# L3INIT_CM_CORE register map
Vendor: Texas Instruments
Peripheral module from a debugger description file (folder omap5430_ES2_PUBLIC).
Registers are 32-bit, access per field, reset 0x70000 unless marked. A register's access mark holds for its fields unless they carry their own. Offsets are as the file gives them; lines under a group give offsets from that group; [hi:lo] are bit positions; {n}, {i} and the like mark numbered series; 'fields as' and 'values as' point back to an identical list; <NAME> marks a mode.

## L3INIT_CM_CORE
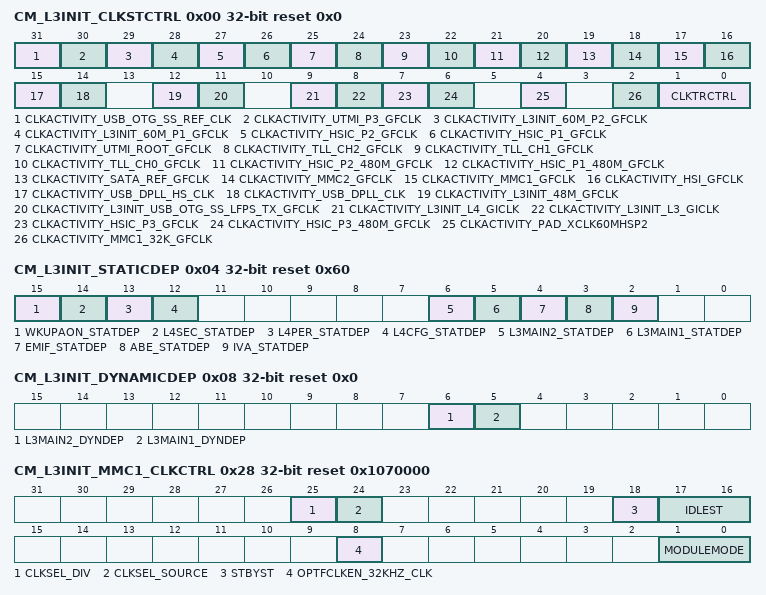
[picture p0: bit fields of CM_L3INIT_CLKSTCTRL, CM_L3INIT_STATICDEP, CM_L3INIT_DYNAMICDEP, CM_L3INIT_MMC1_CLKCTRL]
0x00 CM_L3INIT_CLKSTCTRL reset 0x0 — This register enables the domain power state transition. It controls the HW supervised domain power state transition between ON-ACTIVE and ON-INACTIVE states. It also holds one status bit per clock input of the domain.
  [31] CLKACTIVITY_USB_OTG_SS_REF_CLK ro — This field indicates the state of the USB_OTG_SS_REF_CLK clock in the domain. [warm reset insensitive]
    1=Act (Corresponding clock is running or gating/ungating transition is on-going); 0=Inact (Corresponding clock is definitely gated)
  [30] CLKACTIVITY_UTMI_P3_GFCLK ro — This field indicates the state of the UTMI_P3_GFCLK clock in the domain. [warm reset insensitive]
    values as CLKACTIVITY_USB_OTG_SS_REF_CLK
  [29] CLKACTIVITY_L3INIT_60M_P2_GFCLK ro — This field indicates the state of the INIT_60M_P2_GFCLK clock in the domain. [warm reset insensitive]
    0=Inact (Corresponding clock is definitely gated); 1=Act (Corresponding clock is running or gating/ungating transition is on-going)
  [28] CLKACTIVITY_L3INIT_60M_P1_GFCLK ro — This field indicates the state of the INIT_60M_P1_GFCLK clock in the domain. [warm reset insensitive]
    values as CLKACTIVITY_L3INIT_60M_P2_GFCLK
  [27] CLKACTIVITY_HSIC_P2_GFCLK ro — This field indicates the state of the HSIC_P2_GFCLK clock in the domain. [warm reset insensitive]
    values as CLKACTIVITY_L3INIT_60M_P2_GFCLK
  [26] CLKACTIVITY_HSIC_P1_GFCLK ro — This field indicates the state of the HSIC_P1_GFCLK clock in the domain. [warm reset insensitive]
    values as CLKACTIVITY_L3INIT_60M_P2_GFCLK
  [25] CLKACTIVITY_UTMI_ROOT_GFCLK ro — This field indicates the state of the UTMI_ROOT_GFCLK clock in the domain. [warm reset insensitive]
    values as CLKACTIVITY_L3INIT_60M_P2_GFCLK
  [24] CLKACTIVITY_TLL_CH2_GFCLK ro — This field indicates the state of the TLL_CH2_GFCLK clock in the domain. [warm reset insensitive]
    values as CLKACTIVITY_L3INIT_60M_P2_GFCLK
  [23] CLKACTIVITY_TLL_CH1_GFCLK ro — This field indicates the state of the TLL_CH1_GFCLK clock in the domain. [warm reset insensitive]
    values as CLKACTIVITY_L3INIT_60M_P2_GFCLK
  [22] CLKACTIVITY_TLL_CH0_GFCLK ro — This field indicates the state of the TLL_CH0_GFCLK clock in the domain. [warm reset insensitive]
    values as CLKACTIVITY_L3INIT_60M_P2_GFCLK
  [21] CLKACTIVITY_HSIC_P2_480M_GFCLK ro — This field indicates the state of the HSIC_P2_480M_GFCLK clock in the domain. [warm reset insensitive]
    values as CLKACTIVITY_L3INIT_60M_P2_GFCLK
  [20] CLKACTIVITY_HSIC_P1_480M_GFCLK ro — This field indicates the state of the HSIC_P1_480M_GFCLK clock in the domain. [warm reset insensitive]
    values as CLKACTIVITY_L3INIT_60M_P2_GFCLK
  [19] CLKACTIVITY_SATA_REF_GFCLK ro — This field indicates the state of the SATA_REF_GFCLK clock in the domain. [warm reset insensitive] read 0x0: Corresponding clock is definitely gated read 0x1: Corresponding clock is running or gating/ungating transition is on-going
  [18] CLKACTIVITY_MMC2_GFCLK ro — This field indicates the state of the MMC2_GFCLK clock in the domain. [warm reset insensitive]
    values as CLKACTIVITY_L3INIT_60M_P2_GFCLK
  [17] CLKACTIVITY_MMC1_GFCLK ro — This field indicates the state of the MMC1_GFCLK clock in the domain. [warm reset insensitive]
    values as CLKACTIVITY_L3INIT_60M_P2_GFCLK
  [16] CLKACTIVITY_HSI_GFCLK ro — This field indicates the state of the HSI_GFCLK clock in the domain. [warm reset insensitive]
    values as CLKACTIVITY_L3INIT_60M_P2_GFCLK
  [15] CLKACTIVITY_USB_DPLL_HS_CLK ro — This field indicates the state of the USB_DPLL_HS_CLK clock in the domain. [warm reset insensitive]
    values as CLKACTIVITY_L3INIT_60M_P2_GFCLK
  [14] CLKACTIVITY_USB_DPLL_CLK ro — This field indicates the state of the USB_DPLL_CLK clock in the domain. [warm reset insensitive]
    values as CLKACTIVITY_L3INIT_60M_P2_GFCLK
  [12] CLKACTIVITY_L3INIT_48M_GFCLK ro — This field indicates the state of the L3INIT_48M_GFCLK clock in the domain. [warm reset insensitive]
    values as CLKACTIVITY_L3INIT_60M_P2_GFCLK
  [11] CLKACTIVITY_L3INIT_USB_OTG_SS_LFPS_TX_GFCLK ro — This field indicates the state of the L3INIT_USB_OTG_SS_LFPS_TX_GFCLK clock in the domain.[warm reset insensitive]
    values as CLKACTIVITY_L3INIT_60M_P2_GFCLK
  [9] CLKACTIVITY_L3INIT_L4_GICLK ro — This field indicates the state of the L3INIT_L4_GICLK clock in the domain. [warm reset insensitive]
    values as CLKACTIVITY_L3INIT_60M_P2_GFCLK
  [8] CLKACTIVITY_L3INIT_L3_GICLK ro — This field indicates the state of the L3INIT_L3_GICLK clock in the domain. [warm reset insensitive]
    values as CLKACTIVITY_L3INIT_60M_P2_GFCLK
  [7] CLKACTIVITY_HSIC_P3_GFCLK ro — This field indicates the state of the HSIC_P3_GFCLK clock in the domain. [warm reset insensitive]
    values as CLKACTIVITY_L3INIT_60M_P2_GFCLK
  [6] CLKACTIVITY_HSIC_P3_480M_GFCLK ro — This field indicates the state of the HSIC_P3_480M_GFCLK clock in the domain. [warm reset insensitive]
    values as CLKACTIVITY_L3INIT_60M_P2_GFCLK
  [4] CLKACTIVITY_PAD_XCLK60MHSP2 ro — This field indicates the state of the XCLK60MHSP2 clock in the domain. [warm reset insensitive]
    values as CLKACTIVITY_L3INIT_60M_P2_GFCLK
  [2] CLKACTIVITY_MMC1_32K_GFCLK ro — This field indicates the state of the MMC1_32K_GFCLK clock in the domain. [warm reset insensitive]
    0=Corresponding_clock_is_definitely_gated; 1=CLKACTIVITY_MMC1_32K_GFCLK_1_r (Corresponding clock is running or gating/ungating transition is on-going)
  [1:0] CLKTRCTRL rw — Controls the clock state transition of the L3INIT clock domain.
    0=NO_SLEEP (NO_SLEEP: Sleep transition cannot be initiated. Wakeup transition may however occur.); 1=SW_SLEEP (SW_SLEEP: Start a software forced sleep transition on the domain.); 2=SW_WKUP (SW_WKUP: Start a software forced wake-up transition on the domain.); 3=HW_AUTO (HW_AUTO: Automatic transition is enabled. Sleep and wakeup transition are based upon hardware conditions.)
0x04 CM_L3INIT_STATICDEP reset 0x60 — This register controls the static domain dependencies from L3INIT domain towards 'target' domains. It is relevant only for domain having system initiator(s).
  [15] WKUPAON_STATDEP rw — Static dependency towards WKUPAON clock domain
    0=Disabled (Dependency is disabled); 1=Enabled (Dependency is enabled)
  [14] L4SEC_STATDEP rw — Static dependency towards L4SEC clock domain
    0=Dependency_is_disabled; 1=Dependency_is_enabled
  [13] L4PER_STATDEP rw — Static dependency towards L4_PER clock domain
    values as WKUPAON_STATDEP
  [12] L4CFG_STATDEP rw — Static dependency towards L4_CFG clock domain
    values as WKUPAON_STATDEP
  [6] L3MAIN2_STATDEP ro — Static dependency towards L3_MAIN2 clock domain
    1=Enabled (Dependency is enabled)
  [5] L3MAIN1_STATDEP ro — Static dependency towards L3_MAIN1 clock domain
    1=Enabled (Dependency is enabled)
  [4] EMIF_STATDEP rw — Static dependency towards EMIF clock domain
    values as WKUPAON_STATDEP
  [3] ABE_STATDEP rw — Static dependency towards ABE clock domain
    values as WKUPAON_STATDEP
  [2] IVA_STATDEP rw — Static dependency towards IVA clock domain
    values as WKUPAON_STATDEP
0x08 CM_L3INIT_DYNAMICDEP ro reset 0x0 — This register controls the dynamic domain depedencies from L3INIT domain towards 'target' domains. It is relevant only for domain having INTRCONN master port(s).
  [6] L3MAIN2_DYNDEP — Dynamic dependency towards L3_MAIN2 clock domain
    0=Disabled (Dependency is disabled)
  [5] L3MAIN1_DYNDEP — Dynamic dependency towards L3_MAIN1 clock domain
    0=Disabled (Dependency is disabled)
0x28 CM_L3INIT_MMC1_CLKCTRL reset 0x1070000 — This register manages the MMC1 clocks.
  [25] CLKSEL_DIV rw — MMC1 clock divide ratio
    0=MMC1_OPP_NOM._0 (MMC1 clock is divided by 1, to be used for OPP_NOM.); 1=MMC1_clock_is_divided_by_2
  [24] CLKSEL_SOURCE rw — Selects the source of the functional clock.
    0=SEL_128M (128MHz clock derived from DPLL_PER is selected); 1=SEL_192M (192MHz clock derived from DPLL_PER is selected)
  [18] STBYST ro — Module standby status. [warm reset insensitive]
    0=Func (Module is functional (not in standby)); 1=Standby (Module is in standby)
  [17:16] IDLEST ro — Module idle status. [warm reset insensitive]
    0=Func (Module is fully functional, including INTRCONN); 1=Trans (Module is performing transition: wakeup, or sleep, or sleep abortion); 2=Idle (Module is in Idle mode (only INTRCONN part). It is functional if using separate functional clock); 3=Disable (Module is disabled and cannot be accessed)
  [8] OPTFCLKEN_32KHZ_CLK rw — Optional functional clock control.
    0=Optional_functional_clock_is_disabled; 1=Optional_functional_clock_is_enabled
  [1:0] MODULEMODE rw — Control the way mandatory clocks are managed.
    0=DISABLED (Module is disable by SW. Any INTRCONN access to module results in an error, except if resulting from a module wakeup (asynchronous wakeup).); 2=ENABLED (Module is explicitly enabled. Interface clock (if not used for functions) may be gated according to the clock domain state. Functional clocks are guarantied to stay present. As long as in this configuration, power domain sleep transition cannot happen.)
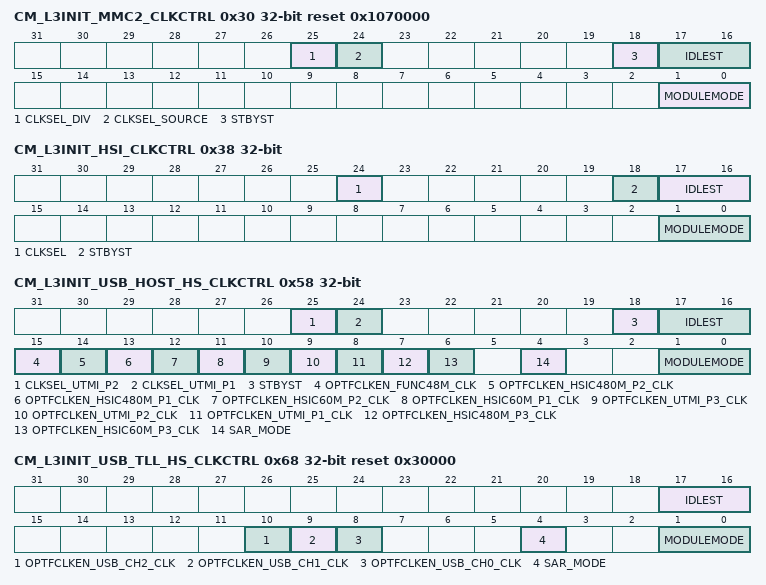
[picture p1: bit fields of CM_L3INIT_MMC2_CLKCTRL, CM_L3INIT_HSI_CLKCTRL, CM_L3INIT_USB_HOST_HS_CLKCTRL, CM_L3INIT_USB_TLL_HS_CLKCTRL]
0x30 CM_L3INIT_MMC2_CLKCTRL reset 0x1070000 — This register manages the MMC2 clocks.
  [25] CLKSEL_DIV rw — MMC2 clock divide ratio 0x0: MMC2 clock is divided by 1, to be used for OPP_NOM. 0x1: MMC2 clock is divided by 2
  [24] CLKSEL_SOURCE rw — Selects the source of the functional clock.
    values as CM_L3INIT_MMC1_CLKCTRL.CLKSEL_SOURCE
  [18] STBYST ro — Module standby status. [warm reset insensitive]
    values as CM_L3INIT_MMC1_CLKCTRL.STBYST
  [17:16] IDLEST ro — Module idle status. [warm reset insensitive]
    values as CM_L3INIT_MMC1_CLKCTRL.IDLEST
  [1:0] MODULEMODE rw — Control the way mandatory clocks are managed.
    0=DISABLED (Module is disable by SW. Any INTRCONN access to module results in an error, except if resulting from a module wakeup (asynchronous wakeup).); 2=ENABLED (Module is explicitly enabled. Interface clock (if not used for functions) may be gated according to the clock domain state. Functional clocks are guaranted to stay present. As long as in this configuration, power domain sleep transition cannot happen.)
0x38 CM_L3INIT_HSI_CLKCTRL — This register manages the HSI clocks.
  [24] CLKSEL rw — Selects the functional clock source.
    0=DIV1 (HSI_FCLK is divide by 1 of 192MHz clock, to be used for OPP_NOM); 1=DIV2 (HSI_FCLK is divide by 2 of 192MHz clock)
  [18] STBYST ro — Module standby status. [warm reset insensitive]
    values as CM_L3INIT_MMC1_CLKCTRL.STBYST
  [17:16] IDLEST ro — Module idle status. [warm reset insensitive]
    values as CM_L3INIT_MMC1_CLKCTRL.IDLEST
  [1:0] MODULEMODE rw — Control the way mandatory clocks are managed.Read 0x: Reserved enum=RESERVED .
    0=DISABLED (Module is disable by SW. Any INTRCONN access to module results in an error, except if resulting from a module wakeup (asynchronous wakeup).); 1=AUTO (Module is managed automatically by HW according to clock domain)
0x58 CM_L3INIT_USB_HOST_HS_CLKCTRL — This register manages the USB_HOST_HS clocks.
  [25] CLKSEL_UTMI_P2 rw — Selects the source of the functional clock for UTMI Port2 on USB_HOST_HS
    0=SEL_INT (The functional clock is provided by the internal clock source); 1=SEL_EXT (The functional clock is provided by an external PHY through an IO pad.)
  [24] CLKSEL_UTMI_P1 rw — Selects the source of the functional clock for UTMI Port1 on USB_HOST_HS
    values as CLKSEL_UTMI_P2
  [18] STBYST ro — Module standby status. [warm reset insensitive]
    values as CM_L3INIT_MMC1_CLKCTRL.STBYST
  [17:16] IDLEST ro — Module idle status. [warm reset insensitive]
    0=Func (Module is fully functional, including Interconnect); 1=Trans (Module is performing transition: wakeup, or sleep, or sleep abortion); 2=Idle (Module is in Idle mode (only Interconnect part). It is functional if using separate functional clock); 3=Disable (Module is disabled and cannot be accessed)
  [15] OPTFCLKEN_FUNC48M_CLK rw — USB_HOST_HS optional clock control: FUNC_48M_CLK
    0=FCLK_DIS (Optional functional clock is disabled); 1=FCLK_EN (Optional functional clock is enabled)
  [14] OPTFCLKEN_HSIC480M_P2_CLK rw — USB_HOST_HS optional clock control: HSIC_P2_480M_GFCLK
    values as OPTFCLKEN_FUNC48M_CLK
  [13] OPTFCLKEN_HSIC480M_P1_CLK rw — USB_HOST_HS optional clock control: HSIC_P1_480M_GFCLK
    values as OPTFCLKEN_FUNC48M_CLK
  [12] OPTFCLKEN_HSIC60M_P2_CLK rw — USB_HOST_HS optional clock control: HSIC_P2_GFCLK
    values as OPTFCLKEN_FUNC48M_CLK
  [11] OPTFCLKEN_HSIC60M_P1_CLK rw — USB_HOST_HS optional clock control: HSIC_P1_GFCLK
    values as OPTFCLKEN_FUNC48M_CLK
  [10] OPTFCLKEN_UTMI_P3_CLK rw — USB_HOST_HS optional clock control: UTMI_P3_GCLK
    values as OPTFCLKEN_FUNC48M_CLK
  [9] OPTFCLKEN_UTMI_P2_CLK rw — USB_HOST_HS optional clock control: UTMI_P2_GCLK when CLKSEL_UTMI_P2 is 0
    values as OPTFCLKEN_FUNC48M_CLK
  [8] OPTFCLKEN_UTMI_P1_CLK rw — USB_HOST_HS optional clock control: UTMI_P1_GCLK when CLKSEL_UTMI_P1 is 0
    values as OPTFCLKEN_FUNC48M_CLK
  [7] OPTFCLKEN_HSIC480M_P3_CLK rw — USB_HOST_HS optional clock control: HSIC_P3_480_GFCLK 0x0: Optional functional clock is disabled 0x1: Optional functional clock is enabled
  [6] OPTFCLKEN_HSIC60M_P3_CLK rw — USB_HOST_HS optional clock control: HSIC_P3_GFCLK 0x0: Optional functional clock is disabled 0x1: Optional functional clock is enabled
  [4] SAR_MODE rw — SAR mode control for the module. Shall not be modify except if module is disabled.
    0=SAR_DIS (SAR mode is disabled); 1=SAR_EN (SAR mode is enabled)
  [1:0] MODULEMODE rw — Control the way mandatory clocks are managed.
    0=DISABLED (Module is disable by SW. Any Interconnect access to module results in an error, except if resulting from a module wakeup (asynchronous wakeup).); 2=ENABLE (Module is explicitly enabled. Interface clock (if not used for functions) may be gated according to the clock domain state. Functional clocks are guarantied to stay present. As long as in this configuration, power domain sleep transition cannot happen.)
0x68 CM_L3INIT_USB_TLL_HS_CLKCTRL reset 0x30000 — This register manages the USB_TLL_HS clocks.
  [17:16] IDLEST ro — Module idle status. [warm reset insensitive]
    values as CM_L3INIT_MMC1_CLKCTRL.IDLEST
  [10] OPTFCLKEN_USB_CH2_CLK rw — USB_TLL_HS optional clock control: USB_CH2_CLK (TLL_CH2_GFCLK)
    values as CM_L3INIT_USB_HOST_HS_CLKCTRL.OPTFCLKEN_FUNC48M_CLK
  [9] OPTFCLKEN_USB_CH1_CLK rw — USB_TLL_HS optional clock control: USB_CH1_CLK (TLL_CH1_GFCLK)
    values as CM_L3INIT_USB_HOST_HS_CLKCTRL.OPTFCLKEN_FUNC48M_CLK
  [8] OPTFCLKEN_USB_CH0_CLK rw — USB_TLL_HS optional clock control: USB_CH0_CLK (TLL_CH0_GFCLK)
    values as CM_L3INIT_USB_HOST_HS_CLKCTRL.OPTFCLKEN_FUNC48M_CLK
  [4] SAR_MODE rw — SAR mode control for the module. Shall not be modify except if module is disabled.
    values as CM_L3INIT_USB_HOST_HS_CLKCTRL.SAR_MODE
  [1:0] MODULEMODE rw — Control the way mandatory clocks are managed.
    0=DISABLED (Module is disable by SW. Any Interconnect access to module results in an error, except if resulting from a module wakeup (asynchronous wakeup).); 1=RESERVED (Module is managed automatically by HW according to clock domain transition. A clock domain sleep transition put module into idle. A wakeup domain transition put it back into function. If[1:0] CLKTRCTRL = 0x3 (HW_AUTO), any Interconnect access to module is always granted. Module clocks may be gated according to the clock domain state.)
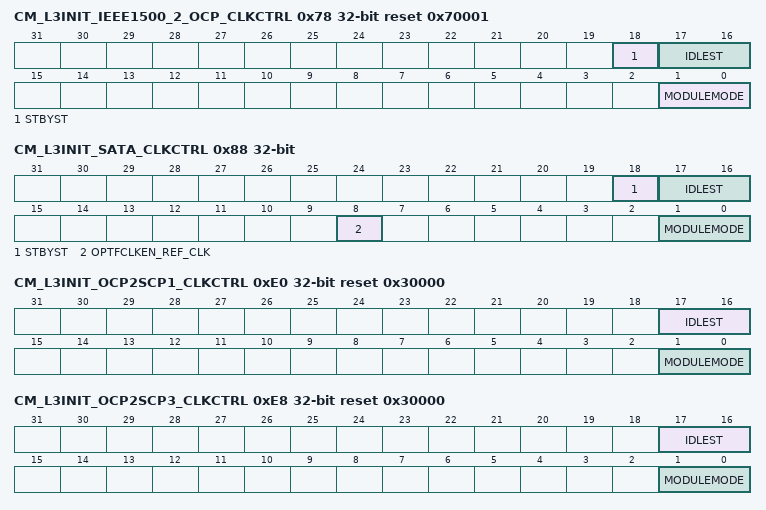
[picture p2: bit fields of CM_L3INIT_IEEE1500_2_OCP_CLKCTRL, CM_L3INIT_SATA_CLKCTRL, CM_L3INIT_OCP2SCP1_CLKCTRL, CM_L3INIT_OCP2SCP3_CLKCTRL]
0x78 CM_L3INIT_IEEE1500_2_OCP_CLKCTRL reset 0x70001 — This register manages the IEEE1500_2_OCP clocks.
  [18] STBYST ro — Module standby status. [warm reset insensitive]
    values as CM_L3INIT_MMC1_CLKCTRL.STBYST
  [17:16] IDLEST ro — Module idle status. [warm reset insensitive]
    values as CM_L3INIT_USB_HOST_HS_CLKCTRL.IDLEST
  [1:0] MODULEMODE rw — Control the way mandatory clocks are managed.
    0=SW._0 (Module is disable by SW. Any Interconnect access to module results in an error, except if resulting from a module wakeup (asynchronous wakeup).); 1=AUTO (Reserved); 2=Module is explicitly enabled. Interface clock (if not used for functions) may be gated according to the clock domain state. Functional clocks are guarantied to stay present. As long as in this configuration, power domain sleep transition cannot happen.
0x88 CM_L3INIT_SATA_CLKCTRL — This register manages the SATA clocks.
  [18] STBYST ro — Module standby status. [warm reset insensitive]
    values as CM_L3INIT_MMC1_CLKCTRL.STBYST
  [17:16] IDLEST ro — Module idle status. [warm reset insensitive]
    values as CM_L3INIT_USB_HOST_HS_CLKCTRL.IDLEST
  [8] OPTFCLKEN_REF_CLK rw — SATA optional clock control: REF_CLK (from SYS_CLK clock) 0x0: Optional functional clock is disabled 0x1: Optional functional clock is enabled
  [1:0] MODULEMODE rw — Control the way mandatory clocks are managed.
    0=DISABLED (Module is disable by SW. Any Interconnect access to module results in an error, except if resulting from a module wakeup (asynchronous wakeup).); 2=ENABLED (Module is explicitly enabled. Interface clock (if not used for functions) may be gated according to the clock domain state. Functional clocks are guarantied to stay present. As long as in this configuration, power domain sleep transition cannot happen.)
0xE0 CM_L3INIT_OCP2SCP1_CLKCTRL reset 0x30000 — This register manages the OCP2SCP1 clocks and the optional clock of USB_PHY_CORE.
  [17:16] IDLEST ro — Module idle status. [warm reset insensitive]
    values as CM_L3INIT_USB_HOST_HS_CLKCTRL.IDLEST
  [1:0] MODULEMODE rw — Control the way mandatory clocks are managed.
    values as CM_L3INIT_USB_TLL_HS_CLKCTRL.MODULEMODE
0xE8 CM_L3INIT_OCP2SCP3_CLKCTRL reset 0x30000 — This register manages the OCP2SCP3 clocks and the optional clock of USB_PHY_CORE.
  fields as CM_L3INIT_OCP2SCP1_CLKCTRL
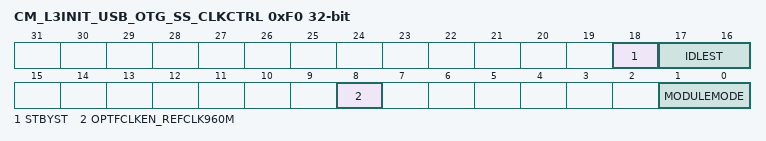
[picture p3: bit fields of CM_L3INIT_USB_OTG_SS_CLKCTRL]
0xF0 CM_L3INIT_USB_OTG_SS_CLKCTRL — This register manages the USB_OTG_SS clocks.
  [18] STBYST ro — Module standby status. [warm reset insensitive]
    values as CM_L3INIT_MMC1_CLKCTRL.STBYST
  [17:16] IDLEST ro — Module idle status. [warm reset insensitive]
    values as CM_L3INIT_USB_HOST_HS_CLKCTRL.IDLEST
  [8] OPTFCLKEN_REFCLK960M rw — USB_OTG_SS optional clock control: L3INIT_960M_GFCLK (960MHz clock)
    values as CM_L3INIT_USB_HOST_HS_CLKCTRL.OPTFCLKEN_FUNC48M_CLK
  [1:0] MODULEMODE rw — Control the way mandatory clocks are managed.
    values as CM_L3INIT_USB_TLL_HS_CLKCTRL.MODULEMODE
